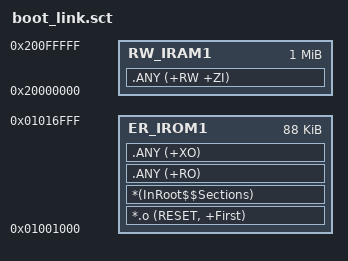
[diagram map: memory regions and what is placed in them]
; ******************************************************************
; *** Scatter-Loading Description File generated by Embedded IDE ***
; ******************************************************************

LR_IROM1 0x01001000 0x00016000 {
	ER_IROM1 0x01001000 0x00016000 {
		*.o (RESET, +First)
		*(InRoot$$Sections)
		.ANY (+RO)
		.ANY (+XO)
	}
	RW_IRAM1 0x20000000 0x0100000 {
		.ANY (+RW +ZI)
	}
}
